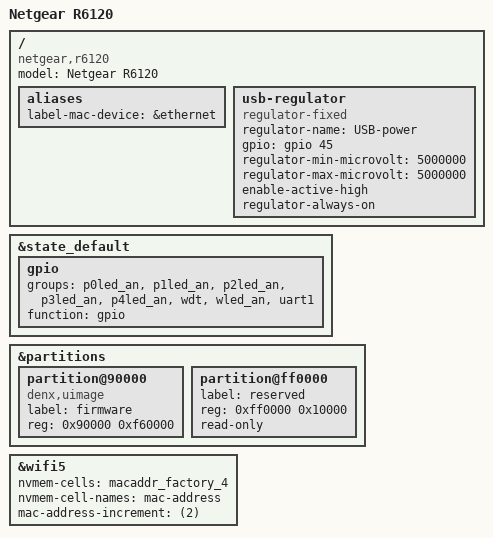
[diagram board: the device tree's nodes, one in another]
#include "mt7628an_netgear_r6xxx.dtsi"

/ {
	compatible = "netgear,r6120", "mediatek,mt7628an-soc";
	model = "Netgear R6120";

	aliases {
		label-mac-device = &ethernet;
	};

	usb-regulator {
		compatible = "regulator-fixed";

		regulator-name = "USB-power";
		gpio = <&gpio 45 GPIO_ACTIVE_HIGH>;
		regulator-min-microvolt = <5000000>;
		regulator-max-microvolt = <5000000>;
		enable-active-high;

		regulator-always-on;
	};
};

&state_default {
	gpio {
		groups = "p0led_an", "p1led_an", "p2led_an", "p3led_an",
		         "p4led_an", "wdt", "wled_an", "uart1";
		function = "gpio";
	};
};

&partitions {
	partition@90000 {
		compatible = "denx,uimage";
		label = "firmware";
		reg = <0x90000 0xf60000>;
	};

	partition@ff0000 {
		label = "reserved";
		reg = <0xff0000 0x10000>;
		read-only;
	};
};

&wifi5 {
	nvmem-cells = <&macaddr_factory_4>;
	nvmem-cell-names = "mac-address";
	mac-address-increment = <(2)>;
};
